# STM32H743 register map
File version: 2.4
CPU: CM7 r0p1, little endian, MPU, FPU, 4 interrupt priority bits
Registers are 32-bit, read-write, reset 0x0 unless marked. A register's access mark holds for its fields unless they carry their own. Offsets are from the block's base; [hi:lo] are bit positions; {n}, {i} and the like mark numbered series; 'fields as' and 'values as' point back to an identical list.

## HRTIM_TIMB — 高分辨率定时器：TIMB
Base 0x40017500
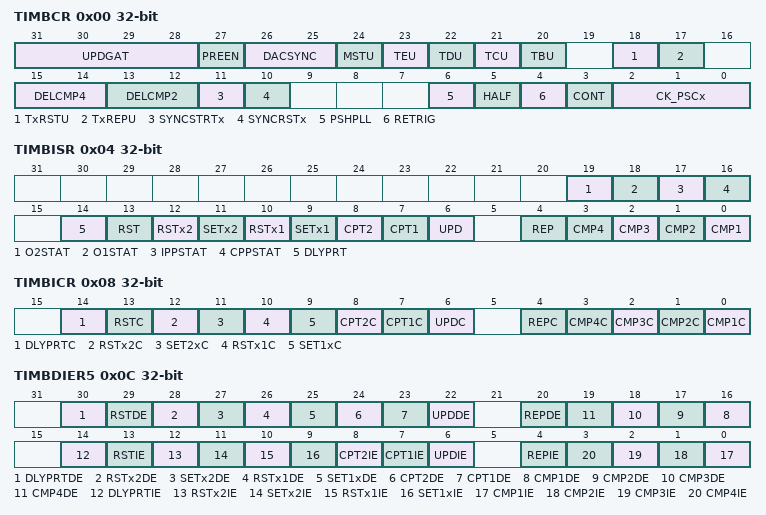
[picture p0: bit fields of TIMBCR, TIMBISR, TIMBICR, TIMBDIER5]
0x00 TIMBCR — Timerx 控制寄存器
  [31:28] UPDGAT — 更新门控
  [27] PREEN — 预装载使能
  [26:25] DACSYNC — AC 同步
  [24] MSTU — 主定时器更新
  [23] TEU
  [22] TDU
  [21] TCU
  [20] TBU
  [18] TxRSTU — Timerx 复位更新
  [17] TxREPU — Timer x 重复更新
  [15:14] DELCMP4 — 延迟 CMP4 模式
  [13:12] DELCMP2 — 延迟 CMP2 模式
  [11] SYNCSTRTx — 同步启动 Timer x
  [10] SYNCRSTx — 同步复位 Timer x
  [6] PSHPLL — 推挽模式使能
  [5] HALF — 半周期模式使能
  [4] RETRIG — 可重触发模式
  [3] CONT — 连续模式
  [2:0] CK_PSCx — HRTIM Timer x 时钟预分频器
0x04 TIMBISR ro — Timerx 中断状态寄存器
  [19] O2STAT — 输出 2 状态
  [18] O1STAT — 输出 1 状态
  [17] IPPSTAT — 空闲推挽状态
  [16] CPPSTAT — 当前推挽状态
  [14] DLYPRT — 延迟保护标志
  [13] RST — 复位中断标志
  [12] RSTx2 — 输出 2 复位中断标志
  [11] SETx2 — 输出 2 置位中断标志
  [10] RSTx1 — 输出 1 复位中断标志
  [9] SETx1 — 输出 1 置位中断标志
  [8] CPT2 — 捕获 2 中断标志
  [7] CPT1 — 捕获 1 中断标志
  [6] UPD — 更新中断标志
  [4] REP — 重复中断标志
  [n-1] CMP{n} (n=1..4) — 比较 {n} 中断标志
0x08 TIMBICR wo — Timerx 中断清除寄存器
  [14] DLYPRTC — 延迟保护标志清除
  [13] RSTC — 复位中断标志清除
  [12] RSTx2C — 输出 2 复位标志清除
  [11] SET2xC — 输出 2 置位标志清除
  [10] RSTx1C — 输出 1 复位标志清除
  [9] SET1xC — 输出 1 置位标志清除
  [8] CPT2C — 捕获 2 中断标志清除
  [7] CPT1C — 捕获 1 中断标志清除
  [6] UPDC — 更新中断标志清除
  [4] REPC — 重复中断标志清除
  [n-1] CMP{n}C (n=1..4) — 比较 {n} 中断标志清除
0x0C TIMBDIER5 — TIMxDIER5
  [30] DLYPRTDE, [29] RSTDE, [28] RSTx2DE, [27] SETx2DE, [26] RSTx1DE, [25] SET1xDE, [24] CPT2DE, [23] CPT1DE, [22] UPDDE, [20] REPDE, [n+15] CMP{n}DE (n=1..4), [14] DLYPRTIE, [13] RSTIE, [12] RSTx2IE, [11] SETx2IE, [10] RSTx1IE, [9] SET1xIE, [8] CPT2IE, [7] CPT1IE, [6] UPDIE, [4] REPIE, [n-1] CMP{n}IE (n=1..4)
0x10 CNTR — Timerx 计数器寄存器
  [15:0] CNTx — Timerx 计数器值
0x14 PERBR reset 0xFFFF — Timerx 周期寄存器
  [15:0] PERx — Timerx 周期值
0x18 REPBR — Timerx 重复寄存器
  [7:0] REPx — Timerx 重复计数器值
0x1C CMP1BR — Timerx 比较 1 寄存器
  [15:0] CMP1x — Timerx 比较 1 值
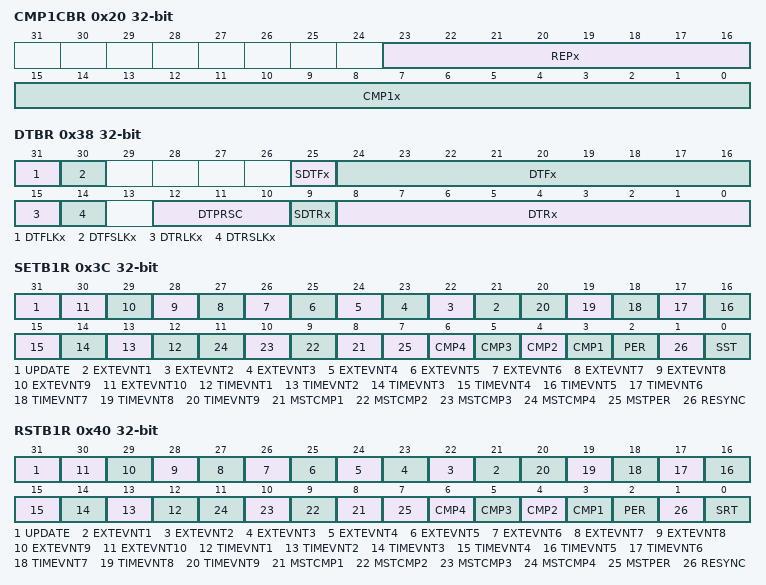
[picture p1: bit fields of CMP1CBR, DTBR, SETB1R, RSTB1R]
0x20 CMP1CBR — Timerx 比较 1 复合寄存器
  [23:16] REPx — Timerx 重复值（从 HRTIM_REPx 寄存器别名而来）
  [15:0] CMP1x — Timerx 比较 1 值
{0x1C+4i} CMP{i}BR (i=2..4) — Timerx 比较 {i} 寄存器
  [15:0] CMP{i}x — Timerx 比较 {i} 值
0x30 CPT1BR ro — Timerx 捕获 1 寄存器
  [15:0] CPT1x — Timerx 捕获 1 值
0x34 CPT2BR ro — Timerx 捕获 2 寄存器
  [15:0] CPT2x — Timerx 捕获 2 值
0x38 DTBR — Timerx 死区寄存器
  [31] DTFLKx — 下降沿死区锁定
  [30] DTFSLKx — 下降沿死区符号锁定
  [25] SDTFx — 下降沿死区符号值
  [24:16] DTFx — 下降沿死区值
  [15] DTRLKx — 上升沿死区锁定
  [14] DTRSLKx — 上升沿死区符号锁定
  [12:10] DTPRSC — 死区预分频器
  [9] SDTRx — 上升沿死区符号值
  [8:0] DTRx — 上升沿死区值
0x3C SETB1R — Timerx 输出 1 置位寄存器
  [31] UPDATE — 寄存器更新（预装载值传输到生效值）
  [n+20] EXTEVNT{n} (n=1..10) — 外部事件 {n}
  [n+11] TIMEVNT{n} (n=1..9) — 定时器事件 {n}
  [n+7] MSTCMP{n} (n=1..4) — 主定时器比较 {n}
  [7] MSTPER — 主定时器周期
  [n+2] CMP{n} (n=1..4) — Timer A 比较 {n}
  [2] PER — Timer A 周期
  [1] RESYNC — Timer A 再同步
  [0] SST — 软件置位触发
0x40 RSTB1R — Timerx 输出 1 复位寄存器
  [31] UPDATE — 寄存器更新（预装载值传输到生效值）
  [n+20] EXTEVNT{n} (n=1..10) — 外部事件 {n}
  [n+11] TIMEVNT{n} (n=1..9) — 定时器事件 {n}
  [n+7] MSTCMP{n} (n=1..4) — 主定时器比较 {n}
  [7] MSTPER — 主定时器周期
  [n+2] CMP{n} (n=1..4) — Timer A 比较 {n}
  [2] PER — Timer A 周期
  [1] RESYNC — Timer A 再同步
  [0] SRT — 软件复位触发
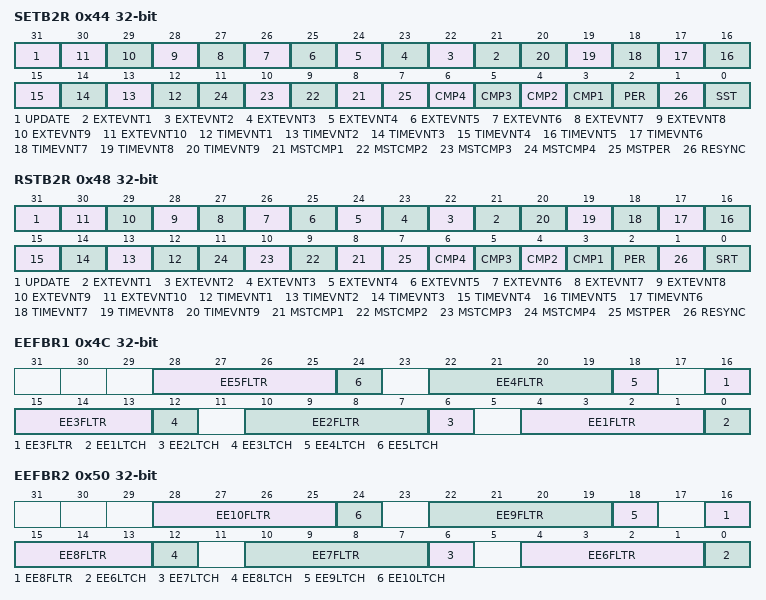
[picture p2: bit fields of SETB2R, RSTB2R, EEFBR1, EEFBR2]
0x44 SETB2R — Timerx 输出 2 置位寄存器
  fields as SETB1R
0x48 RSTB2R — Timerx 输出 2 复位寄存器
  fields as RSTB1R
0x4C EEFBR1 — Timerx 外部事件滤波寄存器 1
  [6n-2:6n-5] EE{n}FLTR (n=1..5) — 外部事件 {n} 滤波
  [6n-6] EE{n}LTCH (n=1..5) — 外部事件 {n} 锁存
0x50 EEFBR2 — Timerx 外部事件滤波寄存器 2
  [6n-32:6n-35] EE{n}FLTR (n=6..10) — 外部事件 {n} 滤波
  [6n-36] EE{n}LTCH (n=6..10) — 外部事件 {n} 锁存
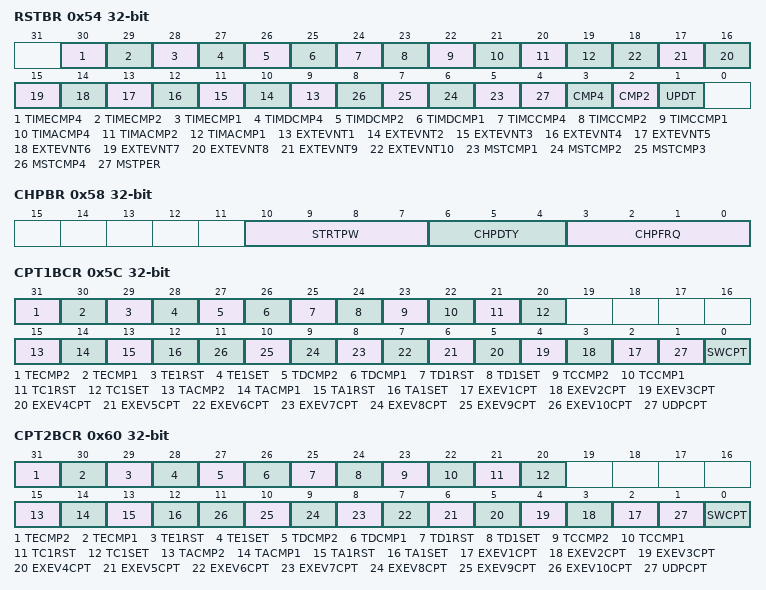
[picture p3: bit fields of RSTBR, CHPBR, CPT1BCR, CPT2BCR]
0x54 RSTBR — TimerA 复位寄存器
  [30] TIMECMP4 — Timer E 比较 4
  [29] TIMECMP2 — Timer E 比较 2
  [28] TIMECMP1 — Timer E 比较 1
  [27] TIMDCMP4 — Timer D 比较 4
  [26] TIMDCMP2 — Timer D 比较 2
  [25] TIMDCMP1 — Timer D 比较 1
  [24] TIMCCMP4 — Timer C 比较 4
  [23] TIMCCMP2 — Timer C 比较 2
  [22] TIMCCMP1 — Timer C 比较 1
  [21] TIMACMP4 — Timer A 比较 4
  [20] TIMACMP2 — Timer A 比较 2
  [19] TIMACMP1 — Timer A 比较 1
  [n+8] EXTEVNT{n} (n=1..10) — 外部事件 {n}
  [n+4] MSTCMP{n} (n=1..4) — 主定时器比较 {n}
  [4] MSTPER — 主定时器周期
  [3] CMP4 — Timer A 比较 4 复位
  [2] CMP2 — Timer A 比较 2 复位
  [1] UPDT — Timer A 更新复位
0x58 CHPBR — Timerx 斩波寄存器
  [10:7] STRTPW
  [6:4] CHPDTY — Timerx 斩波占空比值
  [3:0] CHPFRQ — Timerx 载波频率值
0x5C CPT1BCR — Timerx 捕获 2 控制寄存器
  [31] TECMP2 — Timer E 比较 2
  [30] TECMP1 — Timer E 比较 1
  [29] TE1RST — Timer E 输出 1 复位
  [28] TE1SET — Timer E 输出 1 置位
  [27] TDCMP2 — Timer D 比较 2
  [26] TDCMP1 — Timer D 比较 1
  [25] TD1RST — Timer D 输出 1 复位
  [24] TD1SET — Timer D 输出 1 置位
  [23] TCCMP2 — Timer C 比较 2
  [22] TCCMP1 — Timer C 比较 1
  [21] TC1RST — Timer C 输出 1 复位
  [20] TC1SET — Timer C 输出 1 置位
  [15] TACMP2 — Timer A 比较 2
  [14] TACMP1 — Timer A 比较 1
  [13] TA1RST — Timer A 输出 1 复位
  [12] TA1SET — Timer A 输出 1 置位
  [n+1] EXEV{n}CPT (n=1..10) — 外部事件 {n} 捕获
  [1] UDPCPT — 更新捕获
  [0] SWCPT — 软件捕获
0x60 CPT2BCR — CPT2xCR
  fields as CPT1BCR
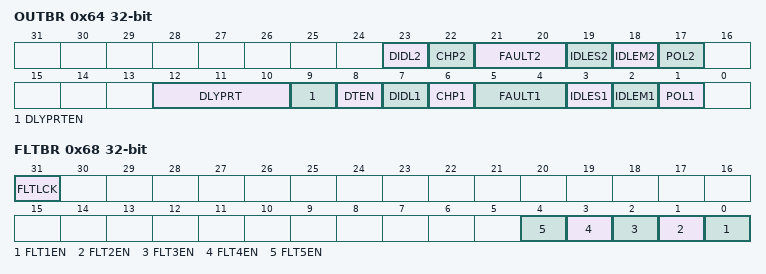
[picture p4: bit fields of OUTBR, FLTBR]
0x64 OUTBR — Timerx 输出寄存器
  [23] DIDL2 — 输出 2 进入突发模式空闲时的死区状态
  [22] CHP2 — 输出 2 斩波使能
  [21:20] FAULT2 — 输出 2 故障状态
  [19] IDLES2 — 输出 2 空闲状态
  [18] IDLEM2 — 输出 2 空闲模式
  [17] POL2 — 输出 2 极性
  [12:10] DLYPRT — 延迟保护
  [9] DLYPRTEN — 延迟保护使能
  [8] DTEN — 死区使能
  [7] DIDL1 — 输出 1 进入突发模式空闲时的死区状态
  [6] CHP1 — 输出 1 斩波使能
  [5:4] FAULT1 — 输出 1 故障状态
  [3] IDLES1 — 输出 1 空闲状态
  [2] IDLEM1 — 输出 1 空闲模式
  [1] POL1 — 输出 1 极性
0x68 FLTBR — Timerx 故障寄存器
  [31] FLTLCK — 故障源锁定
  [n-1] FLT{n}EN (n=1..5) — 故障 {n} 使能
